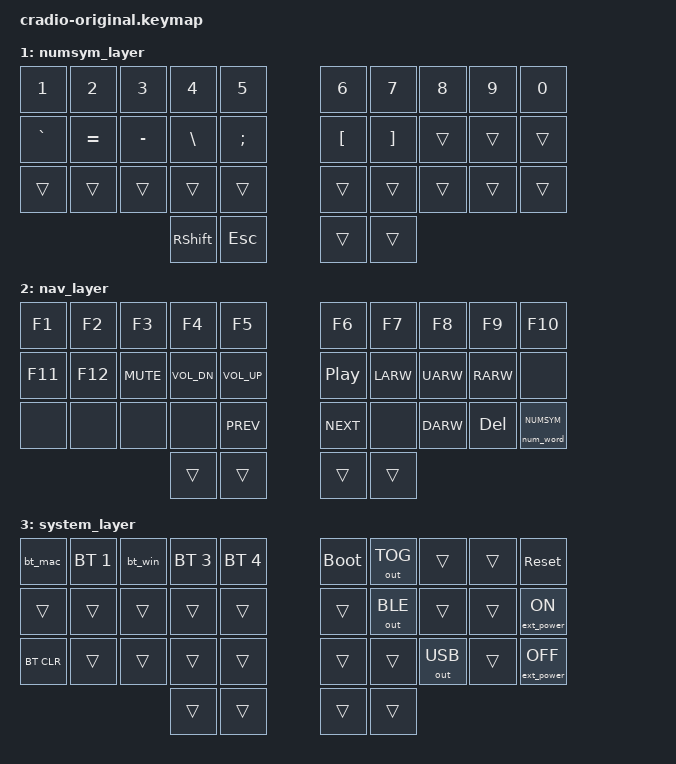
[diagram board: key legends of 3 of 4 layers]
// Copyright (c) 2022 The ZMK Contributors
// SPDX-License-Identifier: MIT

#include <behaviors/num_word.dtsi>
#include <behaviors.dtsi>
#include <dt-bindings/zmk/keys.h>
#include <dt-bindings/zmk/bt.h>
#include <dt-bindings/zmk/outputs.h>
#include <dt-bindings/zmk/ext_power.h>

// ---------- Layer indexes ----------
#define BASE    0 
#define NUMSYM  1
#define NAV     2
#define SYSTEM  3


// ---------- Home-row Mods via single hold-tap ----------
#define HRML(k1,k2,k3,k4) &ht LSHFT k1  &ht LALT k2   &ht LCTRL k3   &ht LGUI k4
#define HRMR(k1,k2,k3,k4) &ht RGUI k1   &ht RCTRL k2  &ht RALT k3    &ht RSHFT k4

/ {
    behaviors {
        ht: hold_tap {
            compatible = "zmk,behavior-hold-tap";
            #binding-cells = <2>;
            flavor = "tap-preferred";
	    // max ms before a tap becomes a hold
            tapping-term-ms = <200>;
	    // if you tap faster than this, always tap
            quick-tap-ms = <120>;
	    // must be idle this long before next press
            require-prior-idle-ms = <150>;
	    // order: <tap>, <hold>
            bindings = <&kp>, <&kp>;
        };
    };

    // ---------- Profile keys that also pick the output ----------
    macros {
        // macOS: cable when plugged in, profile 0 Bluetooth when not
        bt_mac: bt_mac {
            compatible = "zmk,behavior-macro";
            #binding-cells = <0>;
            bindings = <&out OUT_USB &bt BT_SEL 0>;
        };
        // Windows: always Bluetooth profile 2
        bt_win: bt_win {
            compatible = "zmk,behavior-macro";
            #binding-cells = <0>;
            bindings = <&out OUT_BLE &bt BT_SEL 2>;
        };
    };

    // ---------- Conditional tri-layer ----------
    conditional_layers {
        compatible = "zmk,conditional-layers";
        system_layer {
            if-layers = <NAV NUMSYM>;
            then-layer = <SYSTEM>;
        };
    };

    keymap {
        compatible = "zmk,keymap";
        base_layer {
            bindings = <
        //╭──────────┬──────────┬──────────┬──────────┬──────────╮   ╭──────────┬──────────┬──────────┬──────────┬──────────╮
        //│  Q       │  W       │  E       │  R       │  T       │   │  Y       │  U       │  I       │  O       │  P       │
	     &kp Q      &kp W      &kp E      &kp R      &kp T          &kp Y      &kp U      &kp I      &kp O      &kp P
        //├──────────┼──────────┼──────────┼──────────┼──────────┤   ├──────────┼──────────┼──────────┼──────────┼──────────┤
        //│  A       │  S       │  D       │  F       │  G       │   │  H       │  J       │  K       │  L       │ ' "      │
	     HRML(A,    S,         D,         F)         &kp G          &kp H      HRMR(J,    K,         L,        SQT)
        //├──────────┼──────────┼──────────┼──────────┼──────────┤   ├──────────┼──────────┼──────────┼──────────┼──────────┤
        //│  Z       │  X       │  C       │  V       │  B       │   │  N       │  M       │ , <      │ . >      │ / ?      │
	    &kp Z      &kp X      &kp C      &kp V      &kp B          &kp N      &kp M      &kp COMMA  &kp DOT    &kp FSLH
        //╰──────────┴──────────┴──────────┼──────────┼──────────┤   ├──────────┼──────────┼──────────┴──────────┴──────────╯
                                         &lt NAV TAB   &kp ENTER     &kp BSPC  &lt NUMSYM SPACE
        //                                 ╰──────────┴──────────╯   ╰──────────┴──────────╯
            >;
        };

        numsym_layer {
            bindings = <
        //╭──────────┬──────────┬──────────┬──────────┬──────────╮   ╭──────────┬──────────┬──────────┬──────────┬──────────╮
        //│ 1        │ 2        │ 3        │ 4        │ 5        │   │ 6        │ 7        │ 8        │ 9        │  0       │
            &kp N1     &kp N2     &kp N3     &kp N4     &kp N5         &kp N6     &kp N7     &kp N8     &kp N9     &kp N0
        //├──────────┼──────────┼──────────┼──────────┼──────────┤   ├──────────┼──────────┼──────────┼──────────┼──────────┤
        //│ ` ~      │ = +      │ - _     │  \ |      │  ; :     │   │ [ {      │ ] }      │          │          │          │
            &kp GRAVE   &kp EQUAL  &kp MINUS  &kp BSLH   &kp SEMI       &kp LBKT   &kp RBKT   &trans     &trans     &trans
        //├──────────┼──────────┼──────────┼──────────┼──────────┤   ├──────────┼──────────┼──────────┼──────────┼──────────┤
        //│          │          │          │          │          │   │          │          │          │          │          │
	    &trans     &trans     &trans     &trans     &trans         &trans     &trans     &trans     &trans     &trans
	//╰──────────┴──────────┴──────────┼──────────┼──────────┤   ├──────────┼──────────┼──────────┴──────────┴──────────╯
						&kp RSHFT     &kp ESC        &trans     &trans
        //                                 ╰──────────┴──────────╯   ╰──────────┴──────────╯
            >;
        };

        nav_layer {
            bindings = <
        //╭──────────┬──────────┬──────────┬──────────┬──────────╮   ╭──────────┬──────────┬──────────┬──────────┬──────────╮
        //│  F1      │  F2      │  F3      │  F4      │ F5       │   │  F6      │  F7      │  F8      │  F9      │  F10     │
	     &kp F1      &kp F2     &kp F3     &kp F4    &kp F5          &kp F6     &kp F7     &kp F8     &kp F9     &kp F10
        //├──────────┼──────────┼──────────┼──────────┼──────────┤   ├──────────┼──────────┼──────────┼──────────┼──────────┤
        //│  F11     │  F12     │  Mute    │  VOL DN  │ VOL UP   │   │ PLAY/PS  │  LEFT    │  UP      │ RIGHT    │          │
	     &kp F11    &kp F12   &kp K_MUTE &kp C_VOL_DN &kp C_VOL_UP   &kp C_PP     &kp LARW   &kp UARW    &kp RARW   &none
        //├──────────┼──────────┼──────────┼──────────┼──────────┤   ├──────────┼──────────┼──────────┼──────────┼──────────┤
        //│          │          │          │          │ PREV     │   │ NEXT     │          │ DOWN     │   DEL    │          │
	     &none     &none       &none      &none      &kp C_PREV     &kp C_NEXT  &none       &kp DARW    &kp DEL  &num_word NUMSYM
        //╰──────────┴──────────┴──────────┼──────────┼──────────┤   ├──────────┼──────────┼──────────┴──────────┴──────────╯
	                                             &trans     &trans         &trans     &trans
        //                                 ╰──────────┴──────────╯   ╰──────────┴──────────╯
            >;
        };

        system_layer {
            bindings = <
        //╭──────────┬──────────┬──────────┬──────────┬──────────╮   ╭──────────┬──────────┬──────────┬──────────┬──────────╮
        //│ MAC USB/0│ PROFILE 1│ WIN BT 2 │PROFILE 3 │PROFILE 4 │   │BOOTLOADER│ OUT TOG  │          │          │  RESET   │
	&bt_mac       &bt BT_SEL 1 &bt_win      &bt BT_SEL 3  &bt BT_SEL 4       &bootloader &out OUT_TOG &trans      &trans   &sys_reset
        //├──────────┼──────────┼──────────┼──────────┼──────────┤   ├──────────┼──────────┼──────────┼──────────┼──────────┤
        //│          │          │          │          │          │   │          │          │          │          │EP ON     │
	   &trans      &trans     &trans     &trans    &trans          &trans &out OUT_BLE     &trans     &trans  &ext_power EP_ON
        //├──────────┼──────────┼──────────┼──────────┼──────────┤   ├──────────┼──────────┼──────────┼──────────┼──────────┤
        //│ CLEAR BT │          │          │          │	         │   │          │          │          │          │EP OFF    │
	   &bt BT_CLR  &trans     &trans    &trans	&trans          &trans     &trans   &out OUT_USB  &trans  &ext_power EP_OFF
        //╰──────────┴──────────┴──────────┼──────────┼──────────┤   ├──────────┼──────────┼──────────┴──────────┴──────────╯
	                                      &trans     &trans         &trans     &trans
        //                                 ╰──────────┴──────────╯   ╰──────────┴──────────╯
            >;
        };
    };
};

